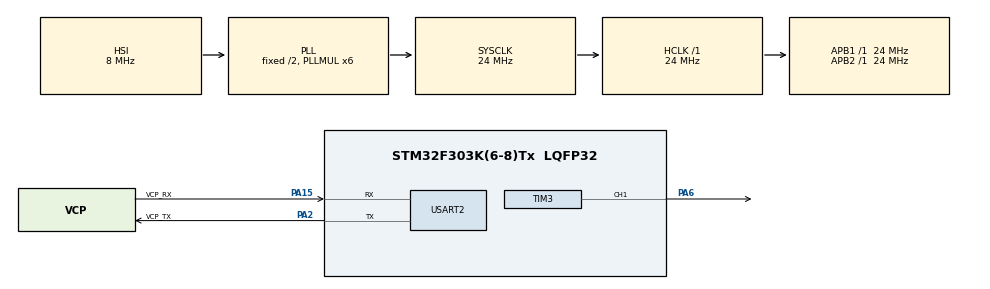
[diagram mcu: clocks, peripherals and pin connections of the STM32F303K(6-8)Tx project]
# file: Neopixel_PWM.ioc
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Dma.Request0=TIM3_CH1/TRIG
Dma.TIM3_CH1/TRIG.0.Direction=DMA_MEMORY_TO_PERIPH
Dma.TIM3_CH1/TRIG.0.Instance=DMA1_Channel6
Dma.TIM3_CH1/TRIG.0.MemDataAlignment=DMA_MDATAALIGN_BYTE
Dma.TIM3_CH1/TRIG.0.MemInc=DMA_MINC_ENABLE
Dma.TIM3_CH1/TRIG.0.Mode=DMA_CIRCULAR
Dma.TIM3_CH1/TRIG.0.PeriphDataAlignment=DMA_PDATAALIGN_HALFWORD
Dma.TIM3_CH1/TRIG.0.PeriphInc=DMA_PINC_DISABLE
Dma.TIM3_CH1/TRIG.0.Priority=DMA_PRIORITY_LOW
Mcu.Family=STM32F3
Mcu.Name=STM32F303K(6-8)Tx
Mcu.Package=LQFP32
NVIC.DMA1_Channel6_IRQn=true\:0\:0\:false\:false\:true\:false\:true\:true
NVIC.PriorityGroup=NVIC_PRIORITYGROUP_4
PA13.GPIO_Label=SWDIO
PA13.Mode=Serial_Wire
PA13.Signal=SYS_JTMS-SWDIO
PA14.GPIO_Label=SWCLK
PA14.Mode=Serial_Wire
PA14.Signal=SYS_JTCK-SWCLK
PA15.GPIO_Label=VCP_RX
PA15.Mode=Asynchronous
PA15.Signal=USART2_RX
PA2.GPIO_Label=VCP_TX
PA2.Mode=Asynchronous
PA2.Signal=USART2_TX
PA6.GPIO_Speed=GPIO_SPEED_FREQ_HIGH
PA6.Signal=S_TIM3_CH1
PF0\ /\ OSC_IN.GPIO_Label=MCO
PF0\ /\ OSC_IN.Mode=HSE-External-Clock-Source
PF0\ /\ OSC_IN.Signal=RCC_OSC_IN
ProjectManager.HeapSize=0x200
ProjectManager.StackSize=0x400
ProjectManager.TargetToolchain=STM32CubeIDE
RCC.AHBFreq_Value=24000000
RCC.APB1Freq_Value=24000000
RCC.APB1TimFreq_Value=24000000
RCC.APB2Freq_Value=24000000
RCC.APB2TimFreq_Value=24000000
RCC.CortexFreq_Value=24000000
RCC.HCLKFreq_Value=24000000
RCC.HSE_VALUE=8000000
RCC.HSI_VALUE=8000000
RCC.PLLMUL=RCC_PLL_MUL6
RCC.SYSCLKFreq_VALUE=24000000
RCC.SYSCLKSourceVirtual=RCC_SYSCLKSOURCE_PLLCLK
SH.S_TIM3_CH1.0=TIM3_CH1,PWM Generation1 CH1
TIM3.Channel-PWM\ Generation1\ CH1=TIM_CHANNEL_1
TIM3.Period=5
TIM3.Prescaler=4
TIM3.TIM_MasterOutputTrigger=TIM_TRGO_OC1REF
TIM3.TIM_MasterSlaveMode=TIM_MASTERSLAVEMODE_ENABLE
USART2.VirtualMode-Asynchronous=VM_ASYNC
board=NUCLEO-F303K8

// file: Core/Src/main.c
/* USER CODE BEGIN Header */
/**
  ******************************************************************************
  * @file           : main.c
  * @brief          : Main program body
  ******************************************************************************
  * @attention
  *
  * Copyright (c) 2024 STMicroelectronics.
  * All rights reserved.
  *
  * This software is licensed under terms that can be found in the LICENSE file
  * in the root directory of this software component.
  * If no LICENSE file comes with this software, it is provided AS-IS.
  *
  ******************************************************************************
  */
/* USER CODE END Header */
#include "main.h"

/* USER CODE BEGIN Includes */

#include "neopixel.h"
/* USER CODE END Includes */

TIM_HandleTypeDef htim3;
DMA_HandleTypeDef hdma_tim3_ch1_trig;

UART_HandleTypeDef huart2;

void SystemClock_Config(void);
static void MX_GPIO_Init(void);
static void MX_DMA_Init(void);
static void MX_USART2_UART_Init(void);
static void MX_TIM3_Init(void);

int main(void)
{

  /* MCU Configuration--------------------------------------------------------*/

  /* Reset of all peripherals, Initializes the Flash interface and the Systick. */
  HAL_Init();

  /* Configure the system clock */
  SystemClock_Config();

  /* Initialize all configured peripherals */
  MX_GPIO_Init();
  MX_DMA_Init();
  MX_USART2_UART_Init();
  MX_TIM3_Init();

  /* Infinite loop */
  while (1)
  {
	  uint8_t  rgb[] = {
	      5,0,0
	  };

	  NeoPixInit (&htim3, TIM_CHANNEL_1);
	  NeoPixStart (rgb, sizeof (rgb));

  }
}

void SystemClock_Config(void)
{
  RCC_OscInitTypeDef RCC_OscInitStruct = {0};
  RCC_ClkInitTypeDef RCC_ClkInitStruct = {0};

  /** Initializes the RCC Oscillators according to the specified parameters
  * in the RCC_OscInitTypeDef structure.
  */
  RCC_OscInitStruct.OscillatorType = RCC_OSCILLATORTYPE_HSI;
  RCC_OscInitStruct.HSIState = RCC_HSI_ON;
  RCC_OscInitStruct.HSICalibrationValue = RCC_HSICALIBRATION_DEFAULT;
  RCC_OscInitStruct.PLL.PLLState = RCC_PLL_ON;
  RCC_OscInitStruct.PLL.PLLSource = RCC_PLLSOURCE_HSI;
  RCC_OscInitStruct.PLL.PLLMUL = RCC_PLL_MUL6;
  if (HAL_RCC_OscConfig(&RCC_OscInitStruct) != HAL_OK)
  {
    Error_Handler();
  }

  /** Initializes the CPU, AHB and APB buses clocks
  */
  RCC_ClkInitStruct.ClockType = RCC_CLOCKTYPE_HCLK|RCC_CLOCKTYPE_SYSCLK
                              |RCC_CLOCKTYPE_PCLK1|RCC_CLOCKTYPE_PCLK2;
  RCC_ClkInitStruct.SYSCLKSource = RCC_SYSCLKSOURCE_PLLCLK;
  RCC_ClkInitStruct.AHBCLKDivider = RCC_SYSCLK_DIV1;
  RCC_ClkInitStruct.APB1CLKDivider = RCC_HCLK_DIV1;
  RCC_ClkInitStruct.APB2CLKDivider = RCC_HCLK_DIV1;

  if (HAL_RCC_ClockConfig(&RCC_ClkInitStruct, FLASH_LATENCY_0) != HAL_OK)
  {
    Error_Handler();
  }
}

static void MX_TIM3_Init(void)
{

  TIM_MasterConfigTypeDef sMasterConfig = {0};
  TIM_OC_InitTypeDef sConfigOC = {0};

  htim3.Instance = TIM3;
  htim3.Init.Prescaler = 4;
  htim3.Init.CounterMode = TIM_COUNTERMODE_UP;
  htim3.Init.Period = 5;
  htim3.Init.ClockDivision = TIM_CLOCKDIVISION_DIV1;
  htim3.Init.AutoReloadPreload = TIM_AUTORELOAD_PRELOAD_DISABLE;
  if (HAL_TIM_PWM_Init(&htim3) != HAL_OK)
  {
    Error_Handler();
  }
  sMasterConfig.MasterOutputTrigger = TIM_TRGO_OC1REF;
  sMasterConfig.MasterSlaveMode = TIM_MASTERSLAVEMODE_ENABLE;
  if (HAL_TIMEx_MasterConfigSynchronization(&htim3, &sMasterConfig) != HAL_OK)
  {
    Error_Handler();
  }
  sConfigOC.OCMode = TIM_OCMODE_PWM1;
  sConfigOC.Pulse = 0;
  sConfigOC.OCPolarity = TIM_OCPOLARITY_HIGH;
  sConfigOC.OCFastMode = TIM_OCFAST_DISABLE;
  if (HAL_TIM_PWM_ConfigChannel(&htim3, &sConfigOC, TIM_CHANNEL_1) != HAL_OK)
  {
    Error_Handler();
  }
  HAL_TIM_MspPostInit(&htim3);

}

static void MX_USART2_UART_Init(void)
{

  huart2.Instance = USART2;
  huart2.Init.BaudRate = 38400;
  huart2.Init.WordLength = UART_WORDLENGTH_8B;
  huart2.Init.StopBits = UART_STOPBITS_1;
  huart2.Init.Parity = UART_PARITY_NONE;
  huart2.Init.Mode = UART_MODE_TX_RX;
  huart2.Init.HwFlowCtl = UART_HWCONTROL_NONE;
  huart2.Init.OverSampling = UART_OVERSAMPLING_16;
  huart2.Init.OneBitSampling = UART_ONE_BIT_SAMPLE_DISABLE;
  huart2.AdvancedInit.AdvFeatureInit = UART_ADVFEATURE_NO_INIT;
  if (HAL_UART_Init(&huart2) != HAL_OK)
  {
    Error_Handler();
  }

}

static void MX_DMA_Init(void)
{

  /* DMA controller clock enable */
  __HAL_RCC_DMA1_CLK_ENABLE();

  /* DMA interrupt init */
  /* DMA1_Channel6_IRQn interrupt configuration */
  HAL_NVIC_SetPriority(DMA1_Channel6_IRQn, 0, 0);
  HAL_NVIC_EnableIRQ(DMA1_Channel6_IRQn);

}

static void MX_GPIO_Init(void)
{

  /* GPIO Ports Clock Enable */
  __HAL_RCC_GPIOF_CLK_ENABLE();
  __HAL_RCC_GPIOA_CLK_ENABLE();

}

void Error_Handler(void)
{
  __disable_irq();
  while (1)
  {
  }
}
